# CW32L031 register map
Vendor: Wuhan Xinyuan Semiconductor Co.,Ltd; Series: CW32L03xx; File version: 1.2
CPU: CM0+ r0p1, little endian, no MPU, no FPU, 3 interrupt priority bits
Registers are 32-bit, read-write, no defined reset value unless marked. A register's access mark holds for its fields unless they carry their own. Offsets are from the block's base; [hi:lo] are bit positions; {n}, {i} and the like mark numbered series.

## FLASH
Base 0x40022000
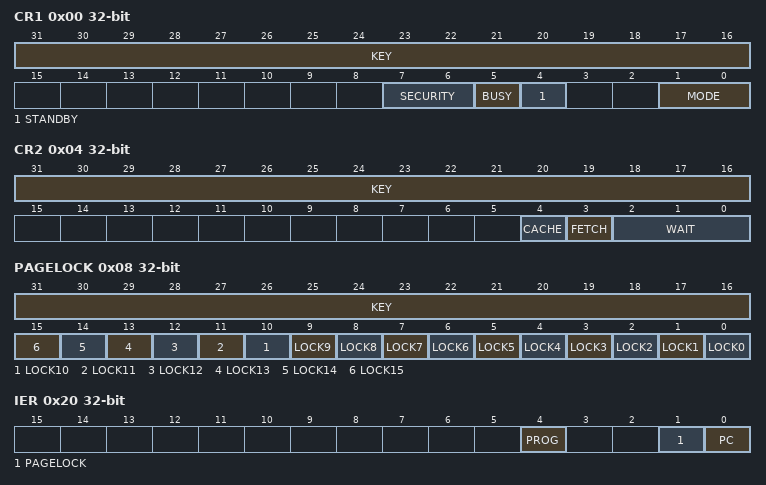
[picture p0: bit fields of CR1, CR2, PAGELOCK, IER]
0x00 CR1 — Control register1
  [31:16] KEY wo, [7:6] SECURITY ro, [5] BUSY ro, [4] STANDBY, [1:0] MODE
0x04 CR2 — Control register2
  [31:16] KEY wo, [4] CACHE, [3] FETCH, [2:0] WAIT
0x08 PAGELOCK — Page Write Erase Lock
  [31:16] KEY wo
  [n] LOCK{n} (n=0..15) — Page{8n} - {8n+7}
0x20 IER — Interrupt enable register
  [4] PROG, [1] PAGELOCK, [0] PC
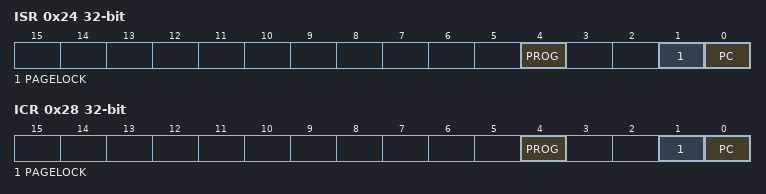
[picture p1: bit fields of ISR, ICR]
0x24 ISR ro — Interrupt status register
  [4] PROG, [1] PAGELOCK, [0] PC
0x28 ICR — Interrupt flag clear register
  [4] PROG, [1] PAGELOCK, [0] PC

## GPIOA
Base 0x48000000
Same registers: GPIOB 0x48000400
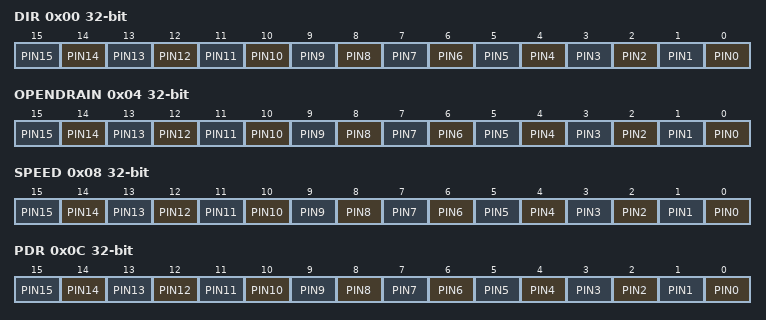
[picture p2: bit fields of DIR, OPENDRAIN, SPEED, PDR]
0x00 DIR
  [n] PIN{n} (n=0..15)
0x04 OPENDRAIN
  [n] PIN{n} (n=0..15)
0x08 SPEED
  [n] PIN{n} (n=0..15)
0x0C PDR
  [n] PIN{n} (n=0..15)
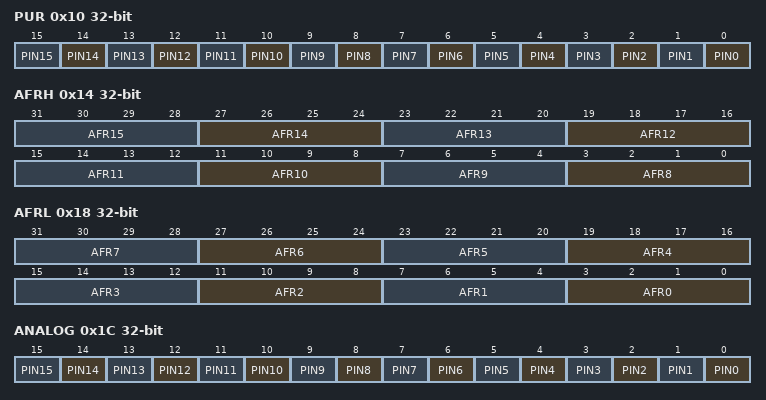
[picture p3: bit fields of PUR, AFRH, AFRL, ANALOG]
0x10 PUR
  [n] PIN{n} (n=0..15)
0x14 AFRH
  [4n-29:4n-32] AFR{n} (n=8..15)
0x18 AFRL
  [4n+3:4n] AFR{n} (n=0..7)
0x1C ANALOG
  [n] PIN{n} (n=0..15)
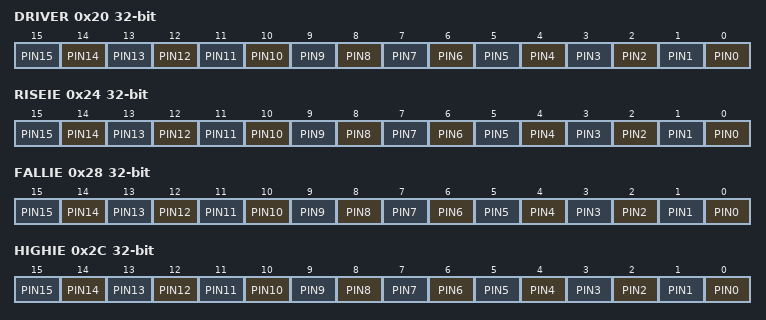
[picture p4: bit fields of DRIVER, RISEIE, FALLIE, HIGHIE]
0x20 DRIVER
  [n] PIN{n} (n=0..15)
0x24 RISEIE — Interrupt enable register
  [n] PIN{n} (n=0..15)
0x28 FALLIE — Interrupt enable register
  [n] PIN{n} (n=0..15)
0x2C HIGHIE — Interrupt enable register
  [n] PIN{n} (n=0..15)
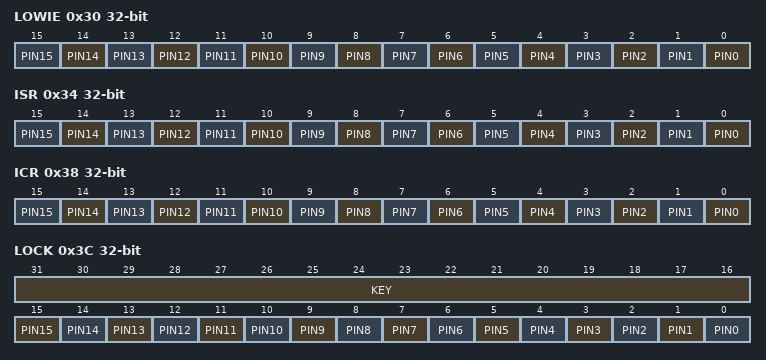
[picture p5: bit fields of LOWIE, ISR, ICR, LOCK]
0x30 LOWIE — Interrupt enable register
  [n] PIN{n} (n=0..15)
0x34 ISR — Interrupt status register
  [n] PIN{n} (n=0..15)
0x38 ICR — Interrupt flag clear register
  [n] PIN{n} (n=0..15)
0x3C LOCK
  [31:16] KEY wo — KEY = 0x5A5A
  [n] PIN{n} (n=0..15)
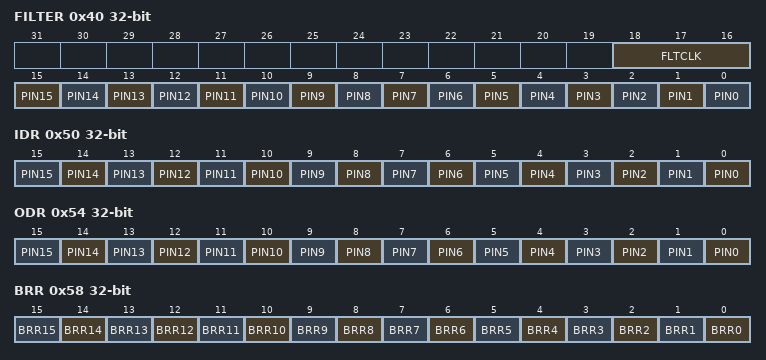
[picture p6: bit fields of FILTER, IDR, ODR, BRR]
0x40 FILTER
  [18:16] FLTCLK, [n] PIN{n} (n=0..15)
0x50 IDR
  [n] PIN{n} (n=0..15)
0x54 ODR
  [n] PIN{n} (n=0..15)
0x54 ODRLOWBYTE 8-bit (alternate view of ODR)
  [7:0] LOWBYTE
0x55 ODRHIGHBYTE 8-bit (alternate view of ODR)
  [7:0] HIGHBYTE
0x58 BRR
  [n] BRR{n} (n=0..15)
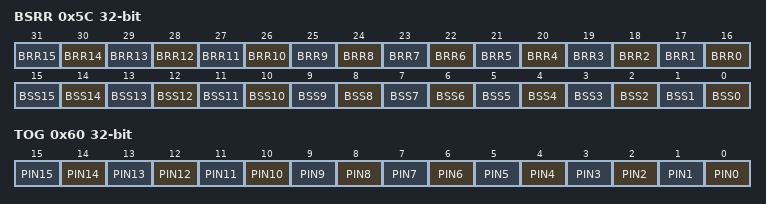
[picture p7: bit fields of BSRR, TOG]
0x5C BSRR
  [n+16] BRR{n} (n=0..15), [n] BSS{n} (n=0..15)
0x60 TOG
  [n] PIN{n} (n=0..15)

## GPIOC
Base 0x48000800
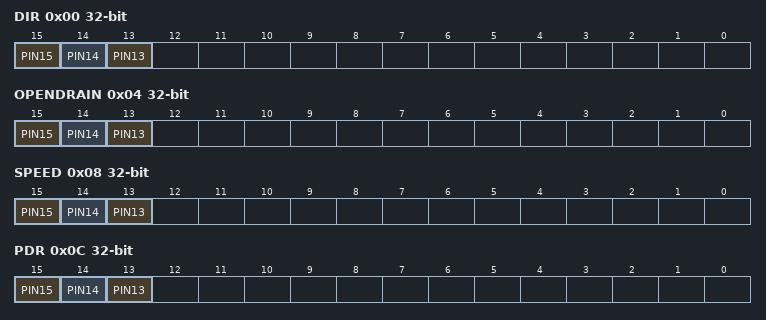
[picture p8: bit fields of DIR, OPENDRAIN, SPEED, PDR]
0x00 DIR
  [15] PIN15, [14] PIN14, [13] PIN13
0x04 OPENDRAIN
  [15] PIN15, [14] PIN14, [13] PIN13
0x08 SPEED
  [15] PIN15, [14] PIN14, [13] PIN13
0x0C PDR
  [15] PIN15, [14] PIN14, [13] PIN13
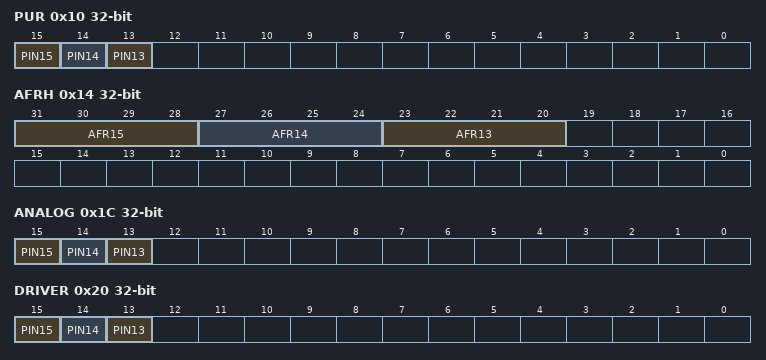
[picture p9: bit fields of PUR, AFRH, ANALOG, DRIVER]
0x10 PUR
  [15] PIN15, [14] PIN14, [13] PIN13
0x14 AFRH
  [31:28] AFR15, [27:24] AFR14, [23:20] AFR13
0x1C ANALOG
  [15] PIN15, [14] PIN14, [13] PIN13
0x20 DRIVER
  [15] PIN15, [14] PIN14, [13] PIN13
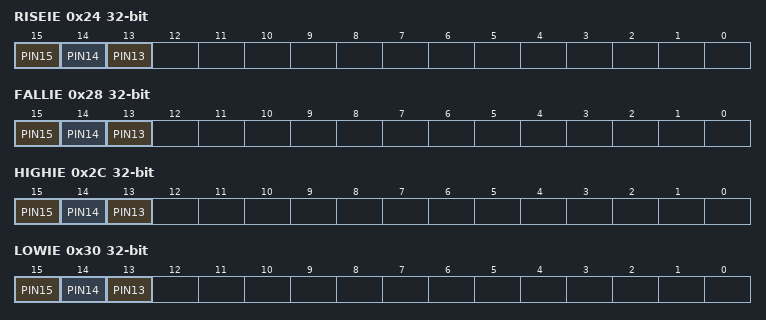
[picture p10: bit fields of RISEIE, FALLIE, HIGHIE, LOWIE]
0x24 RISEIE — Interrupt enable register
  [15] PIN15, [14] PIN14, [13] PIN13
0x28 FALLIE — Interrupt enable register
  [15] PIN15, [14] PIN14, [13] PIN13
0x2C HIGHIE — Interrupt enable register
  [15] PIN15, [14] PIN14, [13] PIN13
0x30 LOWIE — Interrupt enable register
  [15] PIN15, [14] PIN14, [13] PIN13
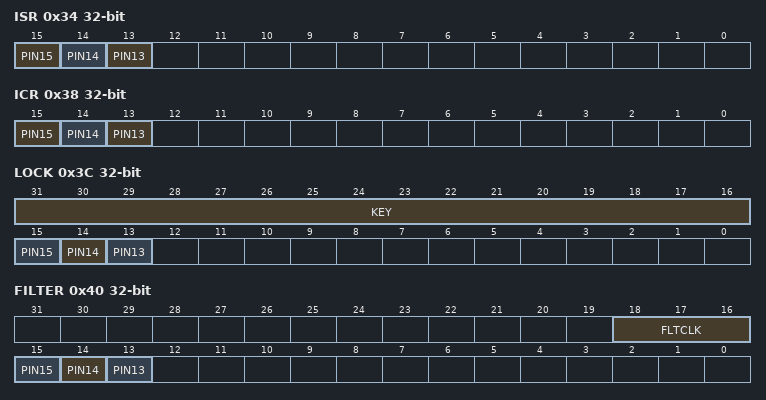
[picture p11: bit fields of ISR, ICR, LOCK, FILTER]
0x34 ISR — Interrupt status register
  [15] PIN15, [14] PIN14, [13] PIN13
0x38 ICR — Interrupt flag clear register
  [15] PIN15, [14] PIN14, [13] PIN13
0x3C LOCK
  [31:16] KEY wo — KEY = 0x5A5A
  [15] PIN15
  [14] PIN14
  [13] PIN13
0x40 FILTER
  [18:16] FLTCLK, [15] PIN15, [14] PIN14, [13] PIN13
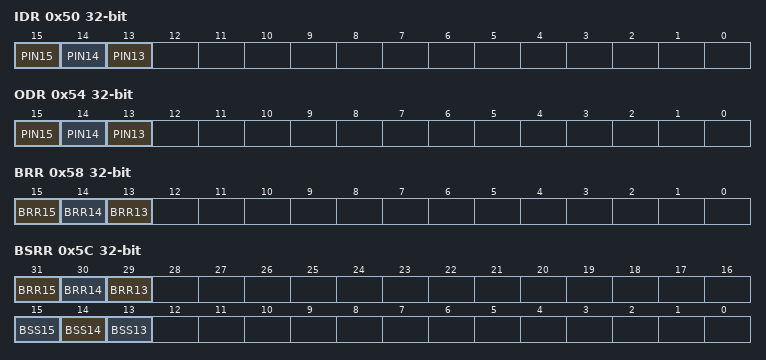
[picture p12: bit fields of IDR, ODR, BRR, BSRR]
0x50 IDR
  [15] PIN15, [14] PIN14, [13] PIN13
0x54 ODR
  [15] PIN15, [14] PIN14, [13] PIN13
0x54 ODRLOWBYTE 8-bit (alternate view of ODR)
  [7:0] LOWBYTE
0x55 ODRHIGHBYTE 8-bit (alternate view of ODR)
  [7:0] HIGHBYTE
0x58 BRR
  [15] BRR15, [14] BRR14, [13] BRR13
0x5C BSRR
  [31] BRR15, [30] BRR14, [29] BRR13, [15] BSS15, [14] BSS14, [13] BSS13
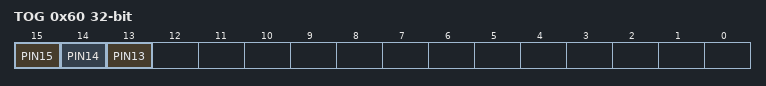
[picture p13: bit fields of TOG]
0x60 TOG
  [15] PIN15, [14] PIN14, [13] PIN13

## GPIOF
Base 0x48001400
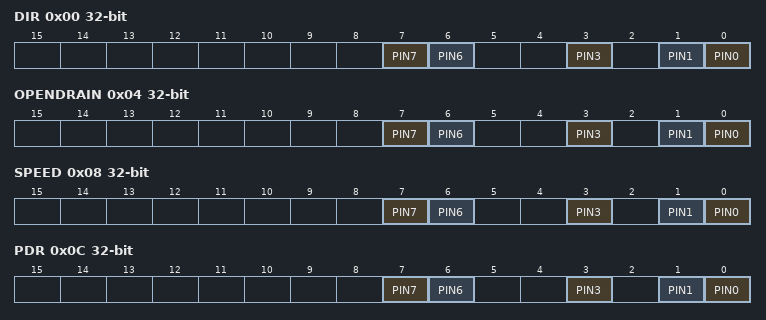
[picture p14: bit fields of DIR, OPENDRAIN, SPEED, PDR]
0x00 DIR
  [7] PIN7, [6] PIN6, [3] PIN3, [1] PIN1, [0] PIN0
0x04 OPENDRAIN
  [7] PIN7, [6] PIN6, [3] PIN3, [1] PIN1, [0] PIN0
0x08 SPEED
  [7] PIN7, [6] PIN6, [3] PIN3, [1] PIN1, [0] PIN0
0x0C PDR
  [7] PIN7, [6] PIN6, [3] PIN3, [1] PIN1, [0] PIN0
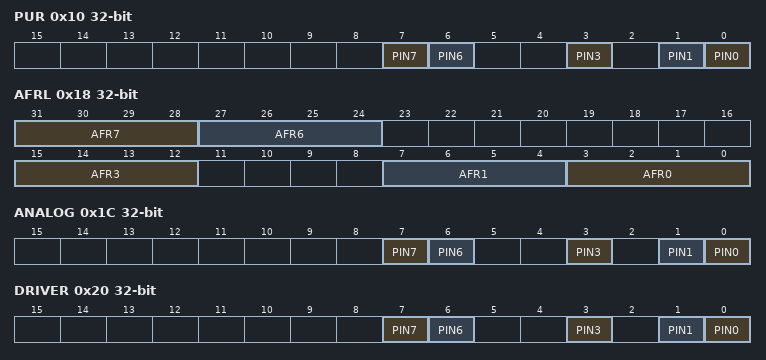
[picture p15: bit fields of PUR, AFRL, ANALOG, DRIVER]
0x10 PUR
  [7] PIN7, [6] PIN6, [3] PIN3, [1] PIN1, [0] PIN0
0x18 AFRL
  [31:28] AFR7, [27:24] AFR6, [15:12] AFR3, [7:4] AFR1, [3:0] AFR0
0x1C ANALOG
  [7] PIN7, [6] PIN6, [3] PIN3, [1] PIN1, [0] PIN0
0x20 DRIVER
  [7] PIN7, [6] PIN6, [3] PIN3, [1] PIN1, [0] PIN0
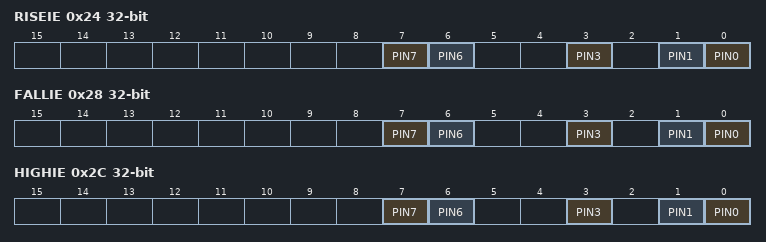
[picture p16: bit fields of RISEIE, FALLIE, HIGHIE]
0x24 RISEIE — Interrupt enable register
  [7] PIN7, [6] PIN6, [3] PIN3, [1] PIN1, [0] PIN0
0x28 FALLIE — Interrupt enable register
  [7] PIN7, [6] PIN6, [3] PIN3, [1] PIN1, [0] PIN0
0x2C HIGHIE — Interrupt enable register
  [7] PIN7, [6] PIN6, [3] PIN3, [1] PIN1, [0] PIN0
0x30 LOWIE — Interrupt enable register
  [7] PIN7, [6] PIN6, [3] PIN3, [1] PIN1, [0] PIN0
0x34 ISR — Interrupt status register
  [7] PIN7, [6] PIN6, [3] PIN3, [1] PIN1, [0] PIN0
0x38 ICR — Interrupt flag clear register
  [7] PIN7, [6] PIN6, [3] PIN3, [1] PIN1, [0] PIN0
0x3C LOCK
  [31:16] KEY wo — KEY = 0x5A5A
  [7] PIN7
  [6] PIN6
  [3] PIN3
  [1] PIN1
  [0] PIN0
0x40 FILTER
  [18:16] FLTCLK, [7] PIN7, [6] PIN6, [3] PIN3, [1] PIN1, [0] PIN0
0x50 IDR
  [7] PIN7, [6] PIN6, [3] PIN3, [1] PIN1, [0] PIN0
0x54 ODR
  [7] PIN7, [6] PIN6, [3] PIN3, [1] PIN1, [0] PIN0
0x54 ODRLOWBYTE 8-bit (alternate view of ODR)
  [7:0] LOWBYTE
0x58 BRR
  [7] BRR7, [6] BRR6, [3] BRR3, [1] BRR1, [0] BRR0
0x5C BSRR
  [7] BSS7, [6] BSS6, [3] BSS3, [1] BSS1, [0] BSS0
0x60 TOG
  [7] PIN7, [6] PIN6, [3] PIN3, [1] PIN1, [0] PIN0
